# FX1 register map
Vendor: FTEL; File version: VP_FX1_V3.0_ISP_1.07
Registers are 32-bit, read-write, reset 0x0 unless marked. A register's access mark holds for its fields unless they carry their own. Offsets are from the block's base; [hi:lo] are bit positions; {n}, {i} and the like mark numbered series; 'fields as' and 'values as' point back to an identical list; <NAME> marks a mode.

## ISP (part 4 of 4) — ISP FX1 v1.07; đủ register/field từ sheet Flat Registers của CSR. Địa chỉ base theo BSP VP_FX1_V3.0; không thay thế xác nhận map silicon.
Base 0x11000000
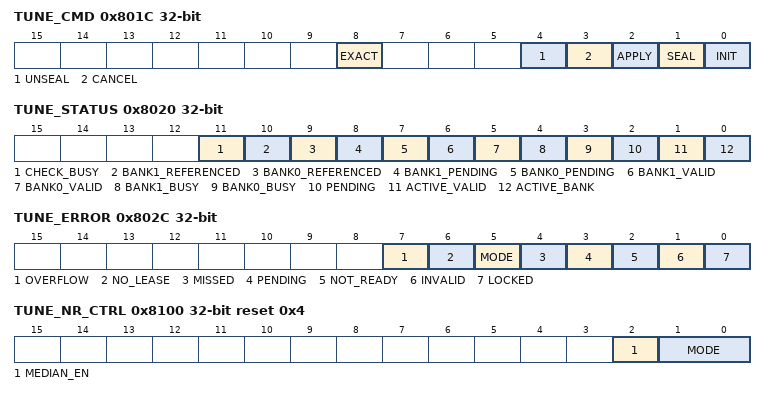
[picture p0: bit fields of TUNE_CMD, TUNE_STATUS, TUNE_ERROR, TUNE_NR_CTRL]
0x801C TUNE_CMD wo write-1-sets — One command per write, except EXACT with APPLY; any other nonzero combination, including EXACT alone, executes nothing and sets INVALID. In legacy mode any nonzero write sets only MODE. SEAL validates but does not activate. UNSEAL permits edits only when inactive, nonpending and unreferenced. APPLY drains the old epoch before activation at an eligible ingress SOF. After SEAL, poll TUNE_STATUS.CHECK_BUSY until clear before inspecting TUNE_ERROR and confirmation flags. [access=w1p]
  [8] EXACT write-1-sets — Modifier on APPLY: require TUNE_APPLY_FRAME equality; otherwise next admitted SOF. [access=w1p]
  [4] UNSEAL write-1-sets — Unlock selected bank only when not active, referenced or pending. [access=w1p]
  [3] CANCEL write-1-sets — Cancel pending request before its ingress acceptance. With no pending request: no effect, no error. [access=w1p]
  [2] APPLY write-1-sets — Snapshot pre-edge TUNE_BANK, selected bank ID and EXACT target. Pending first eligible next edge. Initial profile accepts NEXT or EXACT equal NEXT_FRAME only; farther target INVALID. A rejected APPLY changes nothing and sets one bit, first applicable of MODE, PENDING, NOT_READY (bank not sealed), INVALID, MISSED. [access=w1p]
  [1] SEAL write-1-sets — Validate and seal the selected bank, including required tables and build capabilities; an unsupported requested capability sets INVALID. Poll CHECK_BUSY until clear before reading the result. [access=w1p]
  [0] INIT write-1-sets — Initialize free bank-owned scalars from legacy state and extension defaults; invalidate bank-local payload readiness. Does not copy resident EE scalars, shared LSC mesh shape or live loader ports. [access=w1p]
0x8020 TUNE_STATUS ro — Coherent live controller status. Update: LIVE. MAS v1.07: tuning-profiles. [access=ro]
  [11] CHECK_BUSY — A SEAL or table-validation check is running. If still running after the command write response, CHECK_BUSY is asserted no later than that response; a check completed by then may never be observed busy. After the response, poll until clear before interpreting TUNE_ERROR and confirmation flags. Geometry derivation uses each channel geometry BUSY bit. [access=ro]
  [10] BANK1_REFERENCED — An outstanding frame references bank 1. [access=ro]
  [9] BANK0_REFERENCED — An outstanding frame references bank 0. [access=ro]
  [8] BANK1_PENDING — Bank 1 is the queued APPLY target. [access=ro]
  [7] BANK0_PENDING — Bank 0 is the queued APPLY target. [access=ro]
  [6] BANK1_VALID — Bank 1 sealed. [access=ro]
  [5] BANK0_VALID — Bank 0 sealed. [access=ro]
  [4] BANK1_BUSY — Bank 1 active, referenced, sealed or pending. [access=ro]
  [3] BANK0_BUSY — Bank 0 active, referenced, sealed or pending. [access=ro]
  [2] PENDING — An APPLY is pending. [access=ro]
  [1] ACTIVE_VALID — First profile activated. [access=ro]
  [0] ACTIVE_BANK — Current ingress profile bank. [access=ro]
0x8024 TUNE_ACTIVE_ID ro — Profile of the latest admitted ingress frame; not a substitute for per-frame metadata. Update: LIVE. MAS v1.07: tuning-profiles. [access=ro]
  [31:0] VALUE — Profile of the latest admitted ingress frame; not a substitute for per-frame metadata. [access=ro]
0x8028 TUNE_ACTIVE_FRAME ro — Frame sequence at which the current profile first became active. Update: LIVE. MAS v1.07: tuning-profiles. [access=ro]
  [31:0] VALUE — Frame sequence at which the current profile first became active. [access=ro]
0x802C TUNE_ERROR write-1-clears — Sticky error bits. Hardware set wins over W1C on the same edge. Update: LIVE. MAS v1.07: tuning-profiles. [access=w1c]
  [7] OVERFLOW write-1-clears — A saturating result accumulator overflowed. [access=w1c]
  [6] NO_LEASE write-1-clears — Result access without lease or duplicate lease operation. [access=w1c]
  [5] MODE write-1-clears — Mode changed without drain, legacy command used in extension mode, profile command (TUNE_CMD, TUNE_TABLE_CMD) used in legacy mode, input-domain/IDLE-class write rejected because the pipeline was not idle or profile mode was active, or a TUNE_MODE change while a statistics bank is leased; state is preserved. [access=w1c]
  [4] MISSED write-1-clears — EXACT target already past (d > 2^31) at APPLY acceptance with an active profile; without an active profile INVALID is set instead. CANCEL and DMA recovery do not set MISSED. [access=w1c]
  [3] PENDING write-1-clears — Second APPLY while pending, or software recovery request while COMMON_RECOVERY_STATUS.BUSY. Existing transaction continues. [access=w1c]
  [2] NOT_READY write-1-clears — APPLY of an unsealed bank, a SEAL whose required table is unconfirmed, or a failed table confirmation. [access=w1c]
  [1] INVALID write-1-clears — Invalid field, geometry, table index or command, including a SEAL rule failure, a multi-command or EXACT-only TUNE_CMD write, an EXACT target exactly 2^31 ahead and APPLY of the already active bank. [access=w1c]
  [0] LOCKED write-1-clears — Write, load or confirmation aimed at owned, sealed, pending or referenced storage. [access=w1c]
0x8030 TUNE_NEXT_FRAME ro reset 0x1 — Existing 3A frame counter plus one. First frame is 1 after hard reset; soft resets preserve the counter. Update: LIVE. MAS v1.07: tuning-profiles. [access=ro]
  [31:0] VALUE — Existing 3A frame counter plus one. First frame is 1 after hard reset; soft resets preserve the counter. [access=ro]
{0x8040+4i} TUNE_CH0_BUF{i}_PROFILE ro (i=0..3) — Profile ID published with the existing completed output-buffer metadata. Holds until the buffer next completes successfully. Update: RESULT. MAS v1.07: tuning-profiles. [access=ro]
  [31:0] VALUE — Profile ID published with the existing completed output-buffer metadata. Holds until the buffer next completes successfully. [access=ro]
{0x8050+4i} TUNE_CH1_BUF{i}_PROFILE ro (i=0..3) — Profile ID published with the existing completed output-buffer metadata. Holds until the buffer next completes successfully. Update: RESULT. MAS v1.07: tuning-profiles. [access=ro]
  fields as TUNE_CH0_BUF0_PROFILE
{0x8060+4i} TUNE_CH2_BUF{i}_PROFILE ro (i=0..3) — Profile ID published with the existing completed output-buffer metadata. Holds until the buffer next completes successfully. Update: RESULT. MAS v1.07: tuning-profiles. [access=ro]
  fields as TUNE_CH0_BUF0_PROFILE
0x8100 TUNE_NR_CTRL reset 0x4 — Noise model and median selection. Update: PROFILE. MAS v1.07: tuning-noise. [access=rw]
  [2] MEDIAN_EN — Median prefilter enabled. Disabled path retains matched timing. External: the value is held outside the CSR block; the type is the bus behaviour. [access=rw]
  [1:0] MODE — 0 prior-frame estimate, 1 manual variance, 2 intensity variance LUT, 3 invalid. External: the value is held outside the CSR block; the type is the bus behaviour. [access=rw]
0x8104 TUNE_NR_VARIANCE — Manual noise variance in the existing Haar-coefficient variance units. Update: PROFILE. MAS v1.07: tuning-noise. [access=rw]
  [15:0] VALUE — Manual noise variance in the existing Haar-coefficient variance units. External: the value is held outside the CSR block; the type is the bus behaviour. [access=rw]
0x8108 TUNE_NR_SCALE reset 0x100 — Unsigned Q8.8 variance scale, half-up multiply then clamp. Update: PROFILE. MAS v1.07: tuning-noise. [access=rw]
  [15:0] VALUE — Unsigned Q8.8 variance scale, half-up multiply then clamp. External: the value is held outside the CSR block; the type is the bus behaviour. [access=rw]
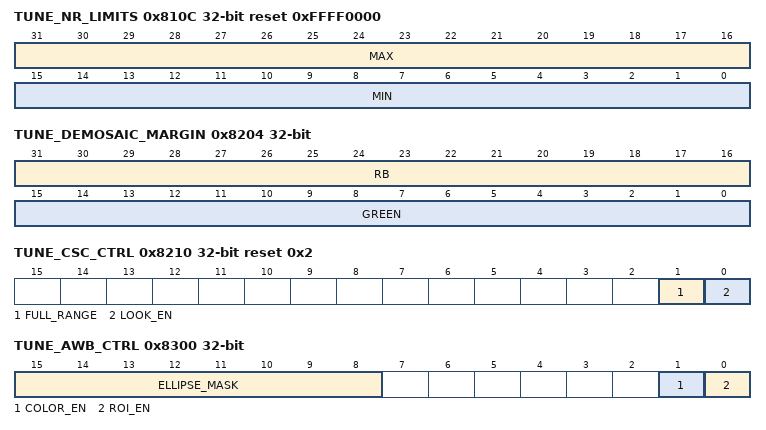
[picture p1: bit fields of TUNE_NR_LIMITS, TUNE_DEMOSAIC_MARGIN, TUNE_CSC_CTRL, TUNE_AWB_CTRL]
0x810C TUNE_NR_LIMITS reset 0xFFFF0000 — Post-scale variance clamp. Update: PROFILE. MAS v1.07: tuning-noise. [access=rw]
  [31:16] MAX — Upper variance bound; SEAL rejects MIN above MAX with INVALID. External: the value is held outside the CSR block; the type is the bus behaviour. [access=rw]
  [15:0] MIN — Lower variance bound. External: the value is held outside the CSR block; the type is the bus behaviour. [access=rw]
0x8110 TUNE_NR_LL_SCALE reset 0x100 — Unsigned Q8.8 multiplier on effective variance for LL; saturate to 16 bits. Update: PROFILE. MAS v1.07: tuning-noise. [access=rw]
  [15:0] VALUE — Unsigned Q8.8 multiplier on effective variance for LL; saturate to 16 bits. External: the value is held outside the CSR block; the type is the bus behaviour. [access=rw]
0x8114 TUNE_NR_LH_SCALE reset 0x100 — Unsigned Q8.8 multiplier on effective variance for LH; saturate to 16 bits. Update: PROFILE. MAS v1.07: tuning-noise. [access=rw]
  [15:0] VALUE — Unsigned Q8.8 multiplier on effective variance for LH; saturate to 16 bits. External: the value is held outside the CSR block; the type is the bus behaviour. [access=rw]
0x8118 TUNE_NR_HL_SCALE reset 0x100 — Unsigned Q8.8 multiplier on effective variance for HL; saturate to 16 bits. Update: PROFILE. MAS v1.07: tuning-noise. [access=rw]
  [15:0] VALUE — Unsigned Q8.8 multiplier on effective variance for HL; saturate to 16 bits. External: the value is held outside the CSR block; the type is the bus behaviour. [access=rw]
0x811C TUNE_NR_HH_SCALE reset 0x100 — Unsigned Q8.8 multiplier on effective variance for HH; saturate to 16 bits. Update: PROFILE. MAS v1.07: tuning-noise. [access=rw]
  [15:0] VALUE — Unsigned Q8.8 multiplier on effective variance for HH; saturate to 16 bits. External: the value is held outside the CSR block; the type is the bus behaviour. [access=rw]
0x8120 TUNE_NR_BLEND reset 0x100 — 0..256: filtered weight in ((256-w)*original+w*filtered+128)>>8. Update: PROFILE. MAS v1.07: tuning-noise. [access=rw]
  [8:0] VALUE — 0..256: filtered weight in ((256-w)*original+w*filtered+128)>>8. External: the value is held outside the CSR block; the type is the bus behaviour. [access=rw]
0x8124 TUNE_NR_LUT_ADDR — Programming index 0..16; no automatic increment. Selected profile bank. Update: PORT. MAS v1.07: tuning-noise. [access=rw]
  [4:0] VALUE — Programming index 0..16; no automatic increment. Selected profile bank. [access=rw]
0x8128 TUNE_NR_LUT_DATA — Variance knot, not sigma. Payload has no reset guarantee; readback selected index. Update: PORT. MAS v1.07: tuning-noise. [access=rw]
  [15:0] VALUE — Variance knot, not sigma. Payload has no reset guarantee; readback selected index. External: the value is held outside the CSR block; the type is the bus behaviour. [access=rw]
0x812C TUNE_NR_SEED — Initial automatic variance after reset or profile switch. Subsequent completed same-profile frames replace it. Update: PROFILE. MAS v1.07: tuning-noise. [access=rw]
  [15:0] VALUE — Initial automatic variance after reset or profile switch. Subsequent completed same-profile frames replace it. External: the value is held outside the CSR block; the type is the bus behaviour. [access=rw]
0x8200 TUNE_WB_GB reset 0x100 — Gb gain UQ4.8. Existing WB_GAIN_G becomes Gr only in extension mode. Update: PROFILE. MAS v1.07: tuning-wb. [access=rw]
  [11:0] VALUE — Gb gain UQ4.8. Existing WB_GAIN_G becomes Gr only in extension mode. External: the value is held outside the CSR block; the type is the bus behaviour. [access=rw]
0x8204 TUNE_DEMOSAIC_MARGIN — Near-equal gradient thresholds, in existing gradient integer units. Update: PROFILE. MAS v1.07: tuning-demosaic. [access=rw]
  [31:16] RB — Use equal-gradient diagonal branch when abs(DN-DP)<=RB. External: the value is held outside the CSR block; the type is the bus behaviour. [access=rw]
  [15:0] GREEN — Use equal-gradient branch when abs(deltaH-deltaV)<=GREEN. External: the value is held outside the CSR block; the type is the bus behaviour. [access=rw]
0x8208 TUNE_CNF_BLEND reset 0x100 — 0..256 filtered chroma weight; 0 original, 256 current CNF result. Update: PROFILE. MAS v1.07: tuning-cnf. [access=rw]
  [8:0] VALUE — 0..256 filtered chroma weight; 0 original, 256 current CNF result. External: the value is held outside the CSR block; the type is the bus behaviour. [access=rw]
0x8210 TUNE_CSC_CTRL reset 0x2 — Frame-profile color controls. Select range coefficients before final CSC rounding; optional look adjustment precedes AF Y8 and downstream YUV processing. [access=rw]
  [1] FULL_RANGE — 1: full-range branch scales and Y offset 0 (default). 0: limited-range scales and Y offset 16. Quantize once after wide range multiplication. Independent of CSC_CTRL.STD. External: the value is held outside the CSR block; the type is the bus behaviour. [access=rw]
  [0] LOOK_EN — Enable brightness/contrast and chroma matrix. External: the value is held outside the CSR block; the type is the bus behaviour. [access=rw]
0x8214 TUNE_CSC_CONTRAST reset 0x100 — Unsigned Q4.8 luma gain around the selected range pedestal. Update: PROFILE. MAS v1.07: tuning-color. [access=rw]
  [11:0] VALUE — Unsigned Q4.8 luma gain around the selected range pedestal. External: the value is held outside the CSR block; the type is the bus behaviour. [access=rw]
0x8218 TUNE_CSC_BRIGHTNESS — Signed two-complement 10-bit luma offset in output Y codes. Update: PROFILE. MAS v1.07: tuning-color. [access=rw]
  [9:0] VALUE — Signed two-complement 10-bit luma offset in output Y codes. External: the value is held outside the CSR block; the type is the bus behaviour. [access=rw]
0x8220 TUNE_CSC_UU reset 0x4000 — Signed Q4.14 chroma-matrix coefficient about neutral 128. Hue/saturation computed by firmware. Update: PROFILE. MAS v1.07: tuning-color. [access=rw]
  [17:0] VALUE — Signed Q4.14 chroma-matrix coefficient about neutral 128. Hue/saturation computed by firmware. External: the value is held outside the CSR block; the type is the bus behaviour. [access=rw]
0x8224 TUNE_CSC_UV — Signed Q4.14 chroma-matrix coefficient about neutral 128. Hue/saturation computed by firmware. Update: PROFILE. MAS v1.07: tuning-color. [access=rw]
  fields as TUNE_CSC_UU
0x8228 TUNE_CSC_VU — Signed Q4.14 chroma-matrix coefficient about neutral 128. Hue/saturation computed by firmware. Update: PROFILE. MAS v1.07: tuning-color. [access=rw]
  fields as TUNE_CSC_UU
0x822C TUNE_CSC_VV reset 0x4000 — Signed Q4.14 chroma-matrix coefficient about neutral 128. Hue/saturation computed by firmware. Update: PROFILE. MAS v1.07: tuning-color. [access=rw]
  fields as TUNE_CSC_UU
0x8300 TUNE_AWB_CTRL — Post-BPC Bayer-cell qualification. Existing strict four-sample clip remains first. Update: PROFILE. MAS v1.07: tuning-awb. [access=rw]
  [15:8] ELLIPSE_MASK — Eight independent color regions; union, count each cell once. External: the value is held outside the CSR block; the type is the bus behaviour. [access=rw]
  [1] COLOR_EN — Apply enabled ellipse union; mask zero accepts no cells. External: the value is held outside the CSR block; the type is the bus behaviour. [access=rw]
  [0] ROI_EN — ROI in complete-cell coordinates. External: the value is held outside the CSR block; the type is the bus behaviour. [access=rw]
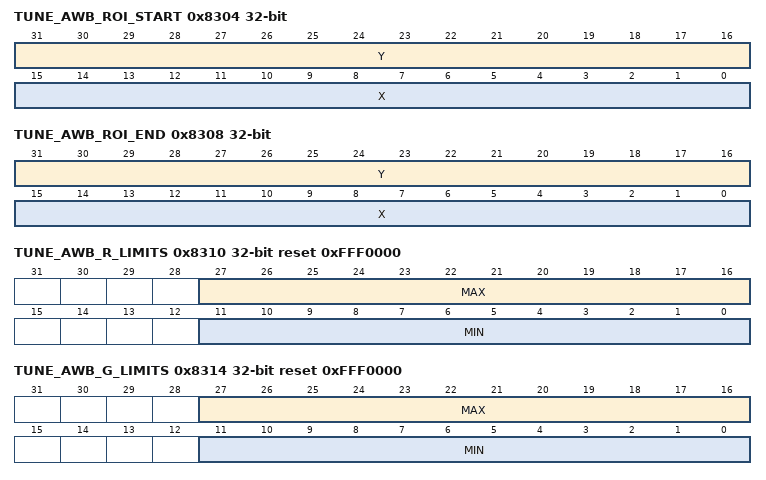
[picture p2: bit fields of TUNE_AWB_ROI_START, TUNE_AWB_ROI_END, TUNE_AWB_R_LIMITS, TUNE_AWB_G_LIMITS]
0x8304 TUNE_AWB_ROI_START — Inclusive start in Bayer-cell coordinates. Update: PROFILE. MAS v1.07: tuning-awb. [access=rw]
  [31:16] Y — Vertical coordinate, inclusive start or exclusive end. External: the value is held outside the CSR block; the type is the bus behaviour. [access=rw]
  [15:0] X — Horizontal coordinate, inclusive start or exclusive end. External: the value is held outside the CSR block; the type is the bus behaviour. [access=rw]
0x8308 TUNE_AWB_ROI_END — Exclusive end in Bayer-cell coordinates. Update: PROFILE. MAS v1.07: tuning-awb. [access=rw]
  fields as TUNE_AWB_ROI_START
0x8310 TUNE_AWB_R_LIMITS reset 0xFFF0000 — Additional inclusive bounds on R; G is half-up mean of Gr/Gb. Update: PROFILE. MAS v1.07: tuning-awb. [access=rw]
  [27:16] MAX — Inclusive upper bound. External: the value is held outside the CSR block; the type is the bus behaviour. [access=rw]
  [11:0] MIN — Inclusive lower bound. External: the value is held outside the CSR block; the type is the bus behaviour. [access=rw]
0x8314 TUNE_AWB_G_LIMITS reset 0xFFF0000 — Additional inclusive bounds on G; G is half-up mean of Gr/Gb. Update: PROFILE. MAS v1.07: tuning-awb. [access=rw]
  fields as TUNE_AWB_R_LIMITS
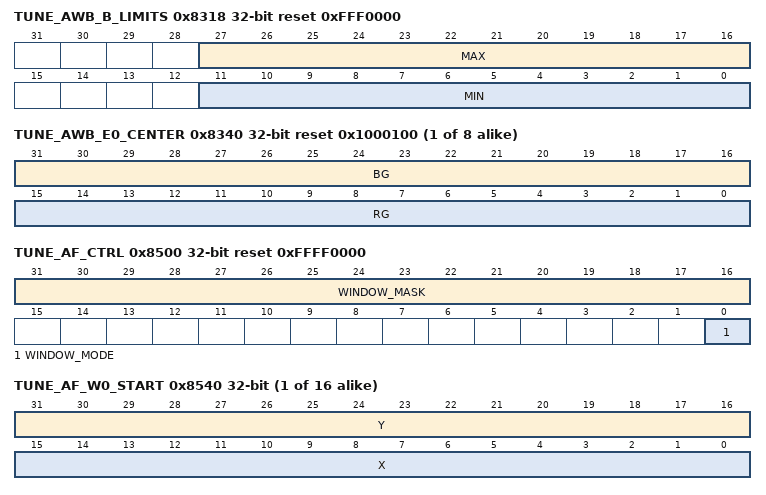
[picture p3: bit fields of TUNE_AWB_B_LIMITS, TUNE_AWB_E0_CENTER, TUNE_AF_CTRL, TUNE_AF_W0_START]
0x8318 TUNE_AWB_B_LIMITS reset 0xFFF0000 — Additional inclusive bounds on B; G is half-up mean of Gr/Gb. Update: PROFILE. MAS v1.07: tuning-awb. [access=rw]
  fields as TUNE_AWB_R_LIMITS
0x831C TUNE_AWB_MIN_G reset 0x1 — Minimum G for color-ratio division. Applies only with COLOR_EN; SEAL rejects 0 with COLOR_EN=1 (INVALID). Update: PROFILE. MAS v1.07: tuning-awb. [access=rw]
  [11:0] VALUE — Minimum G for color-ratio division. Applies only with COLOR_EN; SEAL rejects 0 with COLOR_EN=1 (INVALID). External: the value is held outside the CSR block; the type is the bus behaviour. [access=rw]
{0x8340+0x20*i} TUNE_AWB_E{i}_CENTER reset 0x1000100 (i=0..7) — Ellipse center in unsigned Q8.8 R/G and B/G. Update: PROFILE. MAS v1.07: tuning-awb. [access=rw]
  [31:16] BG — B/G center. External: the value is held outside the CSR block; the type is the bus behaviour. [access=rw]
  [15:0] RG — R/G center. External: the value is held outside the CSR block; the type is the bus behaviour. [access=rw]
{0x8344+0x20*i} TUNE_AWB_E{i}_A reset 0x4000 (i=0..7) — Unsigned Q2.14 diagonal coefficient, must be positive. Update: PROFILE. MAS v1.07: tuning-awb. [access=rw]
  [15:0] VALUE — Unsigned Q2.14 diagonal coefficient, must be positive. External: the value is held outside the CSR block; the type is the bus behaviour. [access=rw]
{0x8348+0x20*i} TUNE_AWB_E{i}_B (i=0..7) — Signed Q1.14 cross coefficient. Update: PROFILE. MAS v1.07: tuning-awb. [access=rw]
  [15:0] VALUE — Signed Q1.14 cross coefficient. External: the value is held outside the CSR block; the type is the bus behaviour. [access=rw]
{0x834C+0x20*i} TUNE_AWB_E{i}_C reset 0x4000 (i=0..7) — Unsigned Q2.14 diagonal coefficient, must be positive. Update: PROFILE. MAS v1.07: tuning-awb. [access=rw]
  fields as TUNE_AWB_E0_A
{0x8350+0x20*i} TUNE_AWB_E{i}_RADIUS2 reset 0x10000 (i=0..7) — Unsigned squared radius in Q16.16; compare metric <= RADIUS2 << 14. Update: PROFILE. MAS v1.07: tuning-awb. [access=rw]
  [31:0] VALUE — Unsigned squared radius in Q16.16; compare metric <= RADIUS2 << 14. External: the value is held outside the CSR block; the type is the bus behaviour. [access=rw]
0x8500 TUNE_AF_CTRL reset 0xFFFF0000 — AF selection at existing CSC Y8 tap. Update: PROFILE. MAS v1.07: tuning-af. [access=rw]
  [31:16] WINDOW_MASK — Enable each metric accumulator. Overlapping windows count independently. External: the value is held outside the CSR block; the type is the bus behaviour. [access=rw]
  [0] WINDOW_MODE — 0 legacy uniform 4x4; 1 sixteen programmable windows. External: the value is held outside the CSR block; the type is the bus behaviour. [access=rw]
0x8504 TUNE_AF_NOISE — Subtract from abs(SobelX)+abs(SobelY), floor at zero before summing. Update: PROFILE. MAS v1.07: tuning-af. [access=rw]
  [11:0] VALUE — Subtract from abs(SobelX)+abs(SobelY), floor at zero before summing. External: the value is held outside the CSR block; the type is the bus behaviour. [access=rw]
{0x8540+8i} TUNE_AF_W{i}_START (i=0..15) — Inclusive full-resolution pixel start. Update: PROFILE. MAS v1.07: tuning-af. [access=rw]
  fields as TUNE_AWB_ROI_START
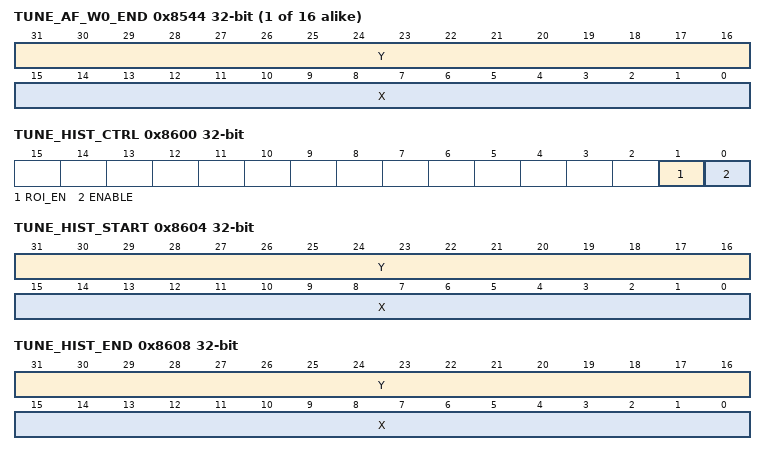
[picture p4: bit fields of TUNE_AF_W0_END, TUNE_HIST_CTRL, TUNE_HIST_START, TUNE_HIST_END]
{0x8544+8i} TUNE_AF_W{i}_END (i=0..15) — Exclusive full-resolution pixel end. Update: PROFILE. MAS v1.07: tuning-af. [access=rw]
  fields as TUNE_AWB_ROI_START
0x8600 TUNE_HIST_CTRL — Additional 64-bin weighted histogram; legacy global histogram remains unchanged. Update: PROFILE. MAS v1.07: tuning-ae. [access=rw]
  [1] ROI_EN — Use programmed ROI; otherwise full frame. External: the value is held outside the CSR block; the type is the bus behaviour. [access=rw]
  [0] ENABLE — Enable weighted histogram. External: the value is held outside the CSR block; the type is the bus behaviour. [access=rw]
0x8604 TUNE_HIST_START — Inclusive pixel start. Update: PROFILE. MAS v1.07: tuning-ae. [access=rw]
  fields as TUNE_AWB_ROI_START
0x8608 TUNE_HIST_END — Exclusive pixel end. Update: PROFILE. MAS v1.07: tuning-ae. [access=rw]
  fields as TUNE_AWB_ROI_START
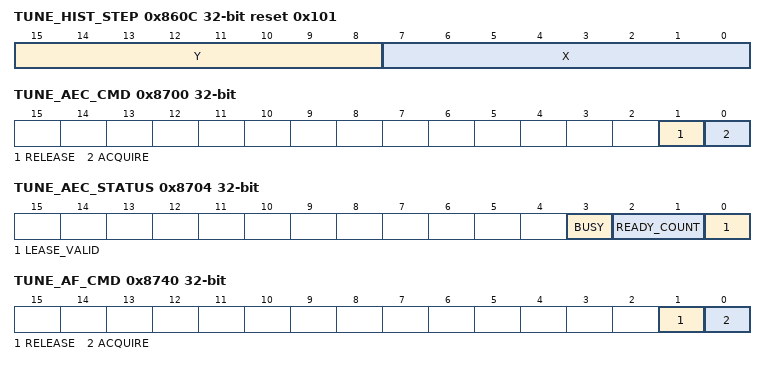
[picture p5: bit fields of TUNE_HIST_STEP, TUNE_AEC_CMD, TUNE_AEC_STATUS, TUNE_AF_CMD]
0x860C TUNE_HIST_STEP reset 0x101 — Sampling lattice anchored at ROI start. Update: PROFILE. MAS v1.07: tuning-ae. [access=rw]
  [15:8] Y — Vertical step 1..255. External: the value is held outside the CSR block; the type is the bus behaviour. [access=rw]
  [7:0] X — Horizontal step 1..255. External: the value is held outside the CSR block; the type is the bus behaviour. [access=rw]
{0x8640+4i} TUNE_HIST_WEIGHT{i} reset 0x1 (i=0..24) — 5x5 spatial weight, row-major. Zero excludes the cell; increment bin by this value. Update: PROFILE. MAS v1.07: tuning-ae. [access=rw]
  [7:0] VALUE — 5x5 spatial weight, row-major. Zero excludes the cell; increment bin by this value. External: the value is held outside the CSR block; the type is the bus behaviour. [access=rw]
0x8700 TUNE_AEC_CMD wo write-1-sets — Two-bank completion-order result lease. RELEASE before ACQUIRE if both are written. Update: COMMAND. MAS v1.07: tuning-ae. [access=w1p]
  [1] RELEASE write-1-sets — Release current lease. No lease sets NO_LEASE. [access=w1p]
  [0] ACQUIRE write-1-sets — Lease oldest READY bank. Duplicate acquire rejected. [access=w1p]
0x8704 TUNE_AEC_STATUS ro — Live lease status. Update: LIVE. MAS v1.07: tuning-ae. [access=ro]
  [3] BUSY — A result bank is being filled or drained. [access=ro]
  [2:1] READY_COUNT — Unleased READY banks 0..2. [access=ro]
  [0] LEASE_VALID — Lease exists. [access=ro]
0x8708 TUNE_AEC_DROPS write-1-clears — Saturating skipped-measurement count. W1C nonzero clears entire word; new drop wins. Update: LIVE. MAS v1.07: tuning-ae. [access=w1c]
  [31:0] VALUE write-1-clears — Saturating skipped-measurement count. W1C nonzero clears entire word; new drop wins. External: the value is held outside the CSR block; the type is the bus behaviour. [access=w1c]
0x870C TUNE_AEC_FRAME ro — Leased ingress frame ID; zero without lease. Update: RESULT. MAS v1.07: tuning-ae. [access=ro]
  [31:0] VALUE — Leased ingress frame ID; zero without lease. [access=ro]
0x8710 TUNE_AEC_PROFILE ro — Leased hardware-applied profile ID; zero without lease. Update: RESULT. MAS v1.07: tuning-ae. [access=ro]
  [31:0] VALUE — Leased hardware-applied profile ID; zero without lease. [access=ro]
0x8714 TUNE_AEC_INDEX — Result index, no autoincrement. Read low first to latch the complete 64-bit value. Update: PORT. MAS v1.07: tuning-ae. [access=rw]
  [15:0] VALUE — Result index, no autoincrement. Read low first to latch the complete 64-bit value. [access=rw]
0x8718 TUNE_AEC_DATA_LO ro — Low 32 bits of selected leased result. Atomically snapshots high word. Update: RESULT. MAS v1.07: tuning-ae. [access=ro]
  [31:0] VALUE — Low 32 bits of selected leased result. Atomically snapshots high word. [access=ro]
0x871C TUNE_AEC_DATA_HI ro — High word of previous low-word snapshot. Invalidated by index write/release/reset. Update: RESULT. MAS v1.07: tuning-ae. [access=ro]
  [31:0] VALUE — High word of previous low-word snapshot. Invalidated by index write/release/reset. [access=ro]
0x8740 TUNE_AF_CMD wo write-1-sets — Two-bank completion-order result lease. RELEASE before ACQUIRE if both are written. Update: COMMAND. MAS v1.07: tuning-af. [access=w1p]
  fields as TUNE_AEC_CMD
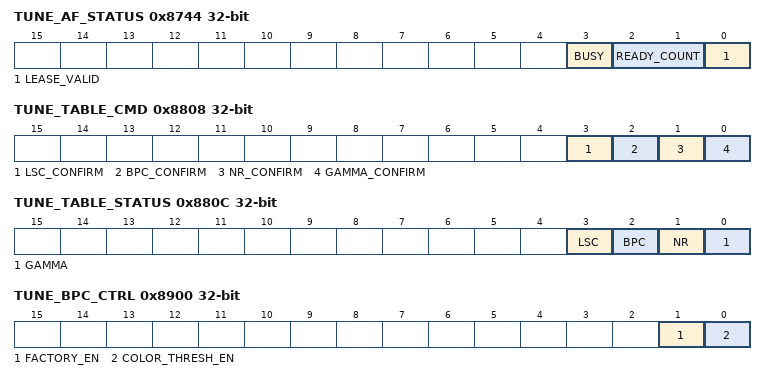
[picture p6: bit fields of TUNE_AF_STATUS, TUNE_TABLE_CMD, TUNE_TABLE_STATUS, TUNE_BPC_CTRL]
0x8744 TUNE_AF_STATUS ro — Live lease status. Update: LIVE. MAS v1.07: tuning-af. [access=ro]
  fields as TUNE_AEC_STATUS
0x8748 TUNE_AF_DROPS write-1-clears — Saturating skipped-measurement count. W1C nonzero clears entire word; new drop wins. Update: LIVE. MAS v1.07: tuning-af. [access=w1c]
  fields as TUNE_AEC_DROPS
0x874C TUNE_AF_FRAME ro — Leased ingress frame ID; zero without lease. Update: RESULT. MAS v1.07: tuning-af. [access=ro]
  fields as TUNE_AEC_FRAME
0x8750 TUNE_AF_PROFILE ro — Leased hardware-applied profile ID; zero without lease. Update: RESULT. MAS v1.07: tuning-af. [access=ro]
  fields as TUNE_AEC_PROFILE
0x8754 TUNE_AF_INDEX — Result index, no autoincrement. Read low first to latch the complete 64-bit value. Update: PORT. MAS v1.07: tuning-af. [access=rw]
  fields as TUNE_AEC_INDEX
0x8758 TUNE_AF_DATA_LO ro — Low 32 bits of selected leased result. Atomically snapshots high word. Update: RESULT. MAS v1.07: tuning-af. [access=ro]
  fields as TUNE_AEC_DATA_LO
0x875C TUNE_AF_DATA_HI ro — High word of previous low-word snapshot. Invalidated by index write/release/reset. Update: RESULT. MAS v1.07: tuning-af. [access=ro]
  fields as TUNE_AEC_DATA_HI
0x8780 TUNE_AWB_PROFILE ro — Profile ID in the existing AWB leased bank. Existing frame ID remains unchanged. Update: RESULT. MAS v1.07: tuning-awb. [access=ro]
  [31:0] VALUE — Profile ID in the existing AWB leased bank. Existing frame ID remains unchanged. [access=ro]
0x8800 TUNE_GAMMA_PORT — Banked 256x12 shared RGB gamma curve. Update: PORT. MAS v1.07: tuning-gamma. [access=rw]
  [7:0] INDEX — Entry index, no autoincrement. [access=rw]
0x8804 TUNE_GAMMA_DATA — Selected profile gamma entry. SRAM has no reset contents; readback supported. Update: PORT. MAS v1.07: tuning-gamma. [access=rw]
  [11:0] VALUE — Selected profile gamma entry. SRAM has no reset contents; readback supported. External: the value is held outside the CSR block; the type is the bus behaviour. [access=rw]
0x8808 TUNE_TABLE_CMD wo write-1-sets — Mark table complete after software writes/readback; hardware checks the payload (MAS table-confirmation rules). A failed check leaves the status bit clear and sets NOT_READY; a sealed, pending or referenced bank sets LOCKED with no effect. Profile-mode command; rejected with TUNE_ERROR.MODE in legacy mode. Update: COMMAND. MAS v1.07: tuning-profiles. [access=w1p]
  [3] LSC_CONFIRM write-1-sets — All sector intervals of the TUNE_BANK-selected configuration bank written, nonzero and covering the mesh span. The bank controller computes Q=floor(65536/d) and R=65536 mod d for each interval by sequenced division. Completes only after all interval constants are stored in that bank. [access=w1p]
  [2] BPC_CONFIRM write-1-sets — TUNE_BPC_COUNT <= 1024 written entries, strictly increasing raster order, every X < W and Y < H. [access=w1p]
  [1] NR_CONFIRM write-1-sets — 17 variance knots required. [access=w1p]
  [0] GAMMA_CONFIRM write-1-sets — 256 gamma entries required. [access=w1p]
0x880C TUNE_TABLE_STATUS ro — Selected-bank confirmed payloads. Payload write clears corresponding confirmation. Update: LIVE. MAS v1.07: tuning-profiles. [access=ro]
  [3] LSC — Confirmed table. [access=ro]
  [2] BPC — Confirmed table. [access=ro]
  [1] NR — Confirmed table. [access=ro]
  [0] GAMMA — Confirmed table. [access=ro]
0x8900 TUNE_BPC_CTRL — Existing BPC detector retained with optional color-specific thresholds and factory map. Update: PROFILE. MAS v1.07: tuning-calibration. [access=rw]
  [1] FACTORY_EN — Correct listed defect coordinates before applying dynamic detector decision. External: the value is held outside the CSR block; the type is the bus behaviour. [access=rw]
  [0] COLOR_THRESH_EN — Use green/RB threshold parameters below. External: the value is held outside the CSR block; the type is the bus behaviour. [access=rw]
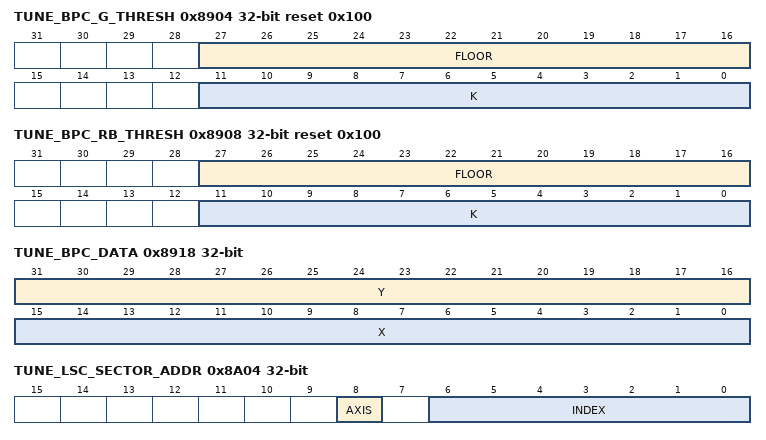
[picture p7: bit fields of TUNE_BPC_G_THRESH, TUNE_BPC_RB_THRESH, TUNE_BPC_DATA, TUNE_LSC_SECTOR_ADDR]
0x8904 TUNE_BPC_G_THRESH reset 0x100 — Color-specific threshold: max(FLOOR,(activity*K+128)>>8). Update: PROFILE. MAS v1.07: tuning-calibration. [access=rw]
  [27:16] FLOOR — Raw12 threshold floor. External: the value is held outside the CSR block; the type is the bus behaviour. [access=rw]
  [11:0] K — Unsigned Q4.8 activity multiplier. External: the value is held outside the CSR block; the type is the bus behaviour. [access=rw]
0x8908 TUNE_BPC_RB_THRESH reset 0x100 — Color-specific threshold: max(FLOOR,(activity*K+128)>>8). Update: PROFILE. MAS v1.07: tuning-calibration. [access=rw]
  fields as TUNE_BPC_G_THRESH
0x8910 TUNE_BPC_COUNT — Factory defect coordinates 0..1024; strict increasing raster order. BPC_CONFIRM checks count, order and bounds; a write clears BPC confirmation. Update: PROFILE. MAS v1.07: tuning-calibration. [access=rw]
  [10:0] VALUE — Factory defect coordinates 0..1024; strict increasing raster order. BPC_CONFIRM checks count, order and bounds; a write clears BPC confirmation. External: the value is held outside the CSR block; the type is the bus behaviour. [access=rw]
0x8914 TUNE_BPC_ADDR — Factory table index 0..1023; no autoincrement. Update: PORT. MAS v1.07: tuning-calibration. [access=rw]
  [9:0] VALUE — Factory table index 0..1023; no autoincrement. [access=rw]
0x8918 TUNE_BPC_DATA — Factory defect x/y in normalized input Bayer coordinates; selected-bank payload. Update: PORT. MAS v1.07: tuning-calibration. [access=rw]
  [31:16] Y — Factory defect point coordinate in the normalized active Bayer image: 0 <= Y < H. This is a pixel location, not a rectangle endpoint. External: the value is held outside the CSR block; the type is the bus behaviour. [access=rw]
  [15:0] X — Factory defect point coordinate in the normalized active Bayer image: 0 <= X < W. This is a pixel location, not a rectangle endpoint. External: the value is held outside the CSR block; the type is the bus behaviour. [access=rw]
0x8A00 TUNE_LSC_CTRL — Existing four gain planes, interpolation and gain precision are retained. Update: PROFILE. MAS v1.07: tuning-lsc. [access=rw]
  [0] SECTOR_EN — In profile mode use the selected bank's confirmed nonuniform sector intervals instead of uniform DDA spacing. Legacy mode stores this field but uses uniform DDA. External: the value is held outside the CSR block; the type is the bus behaviour. [access=rw]
0x8A04 TUNE_LSC_SECTOR_ADDR — Sector extent port. Update: PORT. MAS v1.07: tuning-lsc. [access=rw]
  [8] AXIS — 0 X, 1 Y. [access=rw]
  [6:0] INDEX — Sector index 0..nodes-2, maximum 30 for the integrated 32-node limit. [access=rw]
0x8A08 TUNE_LSC_SECTOR_DATA — Positive interval length in the existing LSC coordinate domain. Sum must equal last-minus-first node coordinate. Update: PORT. MAS v1.07: tuning-lsc. [access=rw]
  [15:0] VALUE — Positive interval length in the existing LSC coordinate domain. Sum must equal last-minus-first node coordinate. External: the value is held outside the CSR block; the type is the bus behaviour. [access=rw]
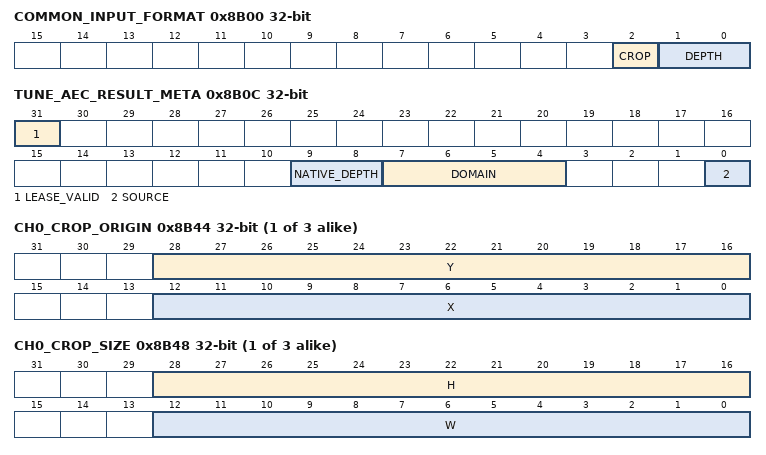
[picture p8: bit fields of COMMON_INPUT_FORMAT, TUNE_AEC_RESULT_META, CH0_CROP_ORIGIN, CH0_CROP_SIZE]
0x8B00 COMMON_INPUT_FORMAT — Native RAW depth and input padding policy. DEPTH[1:0]: 0 RAW12, 1 RAW10, 2/3 invalid. CROP[2]: 0 same-CFA trailing padding (reset), 1 legacy crop. IDLE update; frame-coherent input-domain geometry. [access=rw]
  [2] CROP — 0: nearest same-CFA-colour padding to capped even input size (reset); 1: legacy phase crop. IDLE update. [access=rw]
  [1:0] DEPTH — 0 RAW12 unchanged; 1 RAW10 shifted left two; 2/3 invalid. Both use right-aligned zero-extended 16-bit DDR containers. [access=rw]
0x8B08 TUNE_AEC_SOURCE — AE tap selector, independent of weighting. In profile mode reads/writes the selected editable bank; in legacy mode changes join AEC COMMIT. Capture at ingress and activate at the chosen tap SOF. In legacy mode the last COMMIT accepted before ingress admission selects this frame; later commits apply to a later frame. [access=rw]
  [0] SOURCE — 0 BPC (default); 1 DG after white balance. Both measured as RAW12 Bayer. External: the value is held outside the CSR block; the type is the bus behaviour. [access=rw]
0x8B0C TUNE_AEC_RESULT_META ro — Immutable metadata of the currently acquired AE lease. No-lease read returns zero and sets NO_LEASE. Not live configuration readback. [access=ro]
  [31] LEASE_VALID — 1 if metadata belongs to an acquired AE result. [access=ro]
  [9:8] NATIVE_DEPTH — Measured frame native input encoding: 0 RAW12, 1 RAW10. [access=ro]
  [7:4] DOMAIN — 1 normalized unsigned RAW12 Bayer when leased; 0 without lease. Other encodings reserved. [access=ro]
  [0] SOURCE — 0 BPC, 1 DG; copied from measured frame. [access=ro]
{0x8B40+0x40*i} CH{i}_CROP_CTRL (i=0..2) — Post-shared-IQ YUV crop before this channel resizer. Changes require stop/drain; any accepted geometry write invalidates settled geometry until revalidated. [access=rw]
  [0] ENABLE — 0 full active frame; 1 explicit even crop rectangle. [access=rw]
{0x8B44+0x40*i} CH{i}_CROP_ORIGIN (i=0..2) — Programmed crop geometry in active-frame pixels. Even origin/size, nonempty and fully inside active image. Enabled zero size is invalid. [access=rw]
  [28:16] Y — Vertical coordinate or extent. [access=rw]
  [12:0] X — Horizontal coordinate or extent. [access=rw]
{0x8B48+0x40*i} CH{i}_CROP_SIZE (i=0..2) — Programmed crop geometry in active-frame pixels. Even origin/size, nonempty and fully inside active image. Enabled zero size is invalid. [access=rw]
  [28:16] H — Vertical coordinate or extent. [access=rw]
  [12:0] W — Horizontal coordinate or extent. [access=rw]
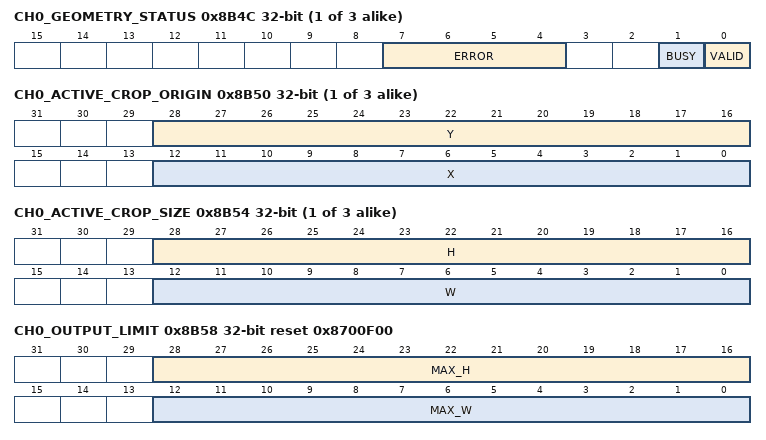
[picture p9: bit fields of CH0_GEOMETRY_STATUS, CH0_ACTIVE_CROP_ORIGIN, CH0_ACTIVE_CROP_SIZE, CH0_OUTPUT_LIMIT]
{0x8B4C+0x40*i} CH{i}_GEOMETRY_STATUS ro (i=0..2) — Current geometry validation state. Last readback is not permission to admit when VALID=0. ERROR is level state, cleared by a valid settled setup; invalid setup also sets sticky TUNE_ERROR.INVALID. [access=ro]
  [7:4] ERROR — Priority code: 0 none; 1 input format/active size; 2 crop empty/out of bounds; 3 odd crop geometry; 4 reserved resize mode; 5 target exceeds channel limit; 6 target exceeds crop. Lowest applicable nonzero code wins. BUSY implies VALID=0 and ERROR=0. [access=ro]
  [1] BUSY — Derivation or validation is pending. [access=ro]
  [0] VALID — 1 only when complete geometry is settled and legal. Reset and any relevant geometry write clear this bit. [access=ro]
{0x8B50+0x40*i} CH{i}_ACTIVE_CROP_ORIGIN ro (i=0..2) — Validated crop snapshot, published atomically with OUT_W/H and VALID. Disabled crop resolves to origin zero and full active size. Zero until first valid setup; retained while invalid/busy, so check VALID. Outstanding frames retain their captured snapshot. [access=ro]
  [28:16] Y — Vertical validated coordinate or extent. [access=ro]
  [12:0] X — Horizontal validated coordinate or extent. [access=ro]
{0x8B54+0x40*i} CH{i}_ACTIVE_CROP_SIZE ro (i=0..2) — Validated crop snapshot, published atomically with OUT_W/H and VALID. Disabled crop resolves to origin zero and full active size. Zero until first valid setup; retained while invalid/busy, so check VALID. Outstanding frames retain their captured snapshot. [access=ro]
  [28:16] H — Vertical validated coordinate or extent. [access=ro]
  [12:0] W — Horizontal validated coordinate or extent. [access=ro]
0x8B58 CH0_OUTPUT_LIMIT ro reset 0x8700F00 — Fixed maximum output extent for this channel; does not authorize upscaling or custom target sizes. [access=ro]
  [28:16] MAX_H — Maximum output height. [access=ro]
  [12:0] MAX_W — Maximum output width. [access=ro]
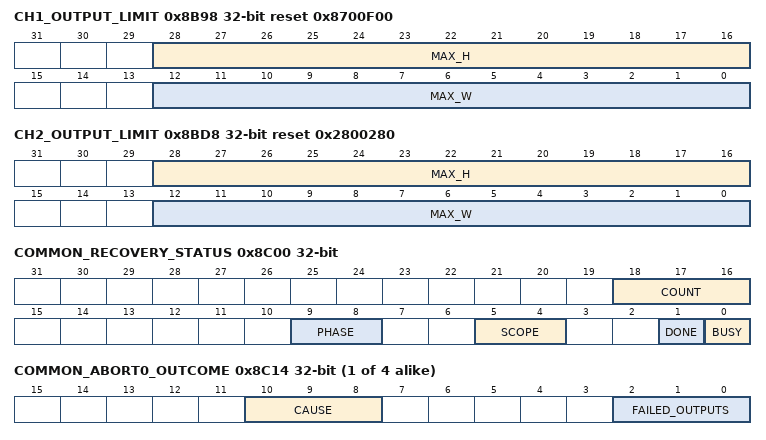
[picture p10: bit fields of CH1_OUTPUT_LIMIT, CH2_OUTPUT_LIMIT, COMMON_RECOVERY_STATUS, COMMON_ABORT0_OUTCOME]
0x8B98 CH1_OUTPUT_LIMIT ro reset 0x8700F00 — Fixed maximum output extent for this channel; does not authorize upscaling or custom target sizes. [access=ro]
  fields as CH0_OUTPUT_LIMIT
0x8BD8 CH2_OUTPUT_LIMIT ro reset 0x2800280 — Fixed maximum output extent for this channel; does not authorize upscaling or custom target sizes. [access=ro]
  fields as CH0_OUTPUT_LIMIT
0x8C00 COMMON_RECOVERY_STATUS — Live recovery status outside soft-reset domains. Read records only with BUSY=0 and a stable recovery sequence. [access=mixed]
  [18:16] COUNT ro — Valid abort-record prefix, 0..4 in ingress admission order. [access=ro]
  [9:8] PHASE ro — 0 idle, 1 bus/internal drain, 2 reset pulse, 3 final retirement. [access=ro]
  [5:4] SCOPE ro — 0 none; 1 DMA/automatic fault recovery; 2 common recovery; 3 reserved. [access=ro]
  [1] DONE write-1-clears — Recovery completed; W1C, hardware set wins. Cleared by each accepted recovery. [access=w1c]
  [0] BUSY ro — Recovery in progress. Do not re-arm DMA until zero. [access=ro]
0x8C04 COMMON_RECOVERY_SEQUENCE ro — Increments modulo 2^32 on each accepted recovery. Only hard reset clears this word. [access=ro]
  [31:0] VALUE — Recovery generation; recheck around record reads. [access=ro]
{0x8C10+8i} COMMON_ABORT{i}_FRAME ro (i=0..3) — Captured ingress frame ID. Valid only within RECOVERY_STATUS.COUNT; unused records read zero. [access=ro]
  [31:0] FRAME — Immutable ingress sequence of an unretired context captured for recovery. [access=ro]
{0x8C14+8i} COMMON_ABORT{i}_OUTCOME ro (i=0..3) — Aborted frame outcome, preserved until next recovery; only hard reset clears outside recovery. [access=ro]
  [10:8] CAUSE — 1 read fault, 2 write fault, 3 DMA command, 4 common command, 5 malformed frame. Simultaneous read/write uses 1; sticky faults retain both. [access=ro]
  [2:0] FAILED_OUTPUTS — CH0/1/2 enabled outputs not successfully retired when recovery was captured. [access=ro]
{0x8C40+4i} TUNE_CH0_BUF{i}_FRAME ro (i=0..3) — Ingress frame ID published with successful DONE and held until the buffer next completes successfully. Preserved by DMA-scope recovery for buffers completed before it; cleared by common and hard reset. [access=ro]
  [31:0] FRAME — Captured ingress sequence; distinct from opaque software tag and DMA frame counters. [access=ro]
{0x8C50+4i} TUNE_CH1_BUF{i}_FRAME ro (i=0..3) — Ingress frame ID published with successful DONE and held until the buffer next completes successfully. Preserved by DMA-scope recovery for buffers completed before it; cleared by common and hard reset. [access=ro]
  fields as TUNE_CH0_BUF0_FRAME
{0x8C60+4i} TUNE_CH2_BUF{i}_FRAME ro (i=0..3) — Ingress frame ID published with successful DONE and held until the buffer next completes successfully. Preserved by DMA-scope recovery for buffers completed before it; cleared by common and hard reset. [access=ro]
  fields as TUNE_CH0_BUF0_FRAME
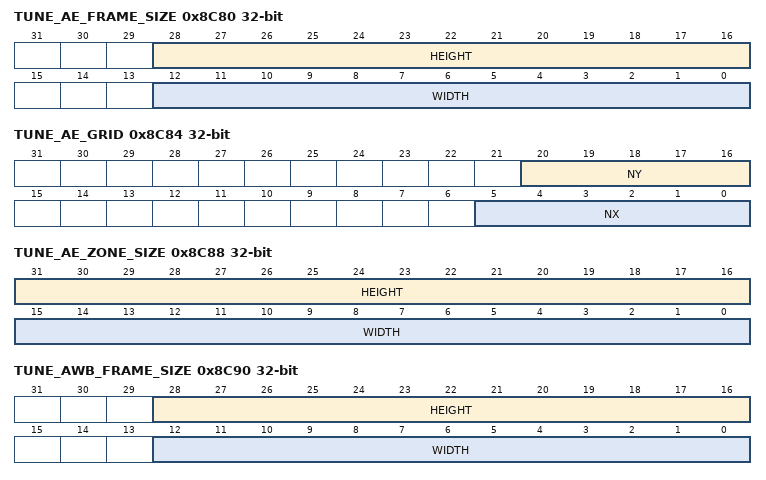
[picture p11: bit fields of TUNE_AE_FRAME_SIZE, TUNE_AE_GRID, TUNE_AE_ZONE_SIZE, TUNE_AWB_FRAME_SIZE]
0x8C80 TUNE_AE_FRAME_SIZE ro — Captured geometry of the acquired statistics frame; immutable under lease. No lease returns zero and sets NO_LEASE. [access=ro]
  [28:16] HEIGHT — Measured full-active-image geometry, independent of current live configuration. [access=ro]
  [12:0] WIDTH — Measured full-active-image geometry, independent of current live configuration. [access=ro]
0x8C84 TUNE_AE_GRID ro — Captured geometry of the acquired statistics frame; immutable under lease. No lease returns zero and sets NO_LEASE. [access=ro]
  [20:16] NY — Measured full-active-image geometry, independent of current live configuration. [access=ro]
  [5:0] NX — Measured full-active-image geometry, independent of current live configuration. [access=ro]
0x8C88 TUNE_AE_ZONE_SIZE ro — Captured geometry of the acquired statistics frame; immutable under lease. No lease returns zero and sets NO_LEASE. [access=ro]
  [31:16] HEIGHT — Measured full-active-image geometry, independent of current live configuration. [access=ro]
  [15:0] WIDTH — Measured full-active-image geometry, independent of current live configuration. [access=ro]
0x8C90 TUNE_AWB_FRAME_SIZE ro — Captured geometry of the acquired statistics frame; immutable under lease. No lease returns zero. [access=ro]
  fields as TUNE_AE_FRAME_SIZE
